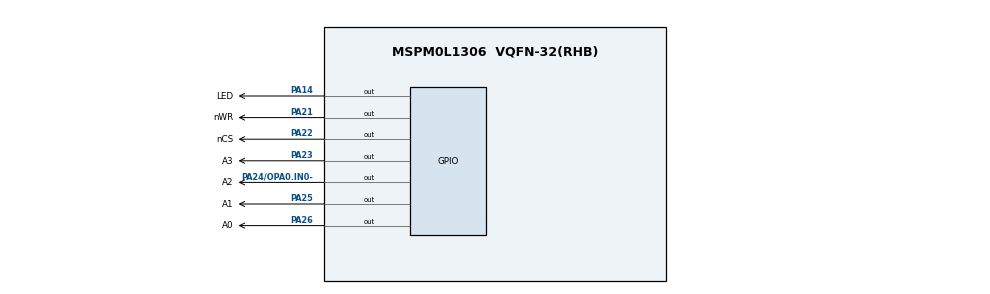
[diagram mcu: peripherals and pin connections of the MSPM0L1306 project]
/**
 * These arguments were used when this file was generated. They will be automatically applied on subsequent loads
 * via the GUI or CLI. Run CLI with '--help' for additional information on how to override these arguments.
 * @cliArgs --device "MSPM0L130X" --part "Default" --package "VQFN-32(RHB)" --product "mspm0_sdk@2.02.00.05"
 * @v2CliArgs --device "MSPM0L1306" --package "VQFN-32(RHB)" --product "mspm0_sdk@2.02.00.05"
 * @versions {"tool":"1.21.0+3721"}
 */

/**
 * Import the modules used in this configuration.
 */
const GPIO          = scripting.addModule("/ti/driverlib/GPIO", {}, false);
const GPIO1         = GPIO.addInstance();
const GPIO2         = GPIO.addInstance();
const SYSCTL        = scripting.addModule("/ti/driverlib/SYSCTL");
const ProjectConfig = scripting.addModule("/ti/project_config/ProjectConfig");

/**
 * Write custom configuration values to the imported modules.
 */
GPIO1.port                          = "PORTA";
GPIO1.portSegment                   = "Lower";
GPIO1.$name                         = "GPIO";
GPIO1.associatedPins[0].$name       = "LED";
GPIO1.associatedPins[0].pin.$assign = "PA14";

const Board = scripting.addModule("/ti/driverlib/Board", {}, false);

GPIO2.$name                         = "GPIO_MUX";
GPIO2.port                          = "PORTA";
GPIO2.portSegment                   = "Upper";
GPIO2.associatedPins.create(6);
GPIO2.associatedPins[0].$name       = "A0";
GPIO2.associatedPins[0].pin.$assign = "PA26";
GPIO2.associatedPins[1].$name       = "A1";
GPIO2.associatedPins[1].pin.$assign = "PA25";
GPIO2.associatedPins[2].$name       = "A2";
GPIO2.associatedPins[2].pin.$assign = "PA24/OPA0.IN0-";
GPIO2.associatedPins[3].$name       = "A3";
GPIO2.associatedPins[3].pin.$assign = "PA23";
GPIO2.associatedPins[4].$name       = "nCS";
GPIO2.associatedPins[4].pin.$assign = "PA22";
GPIO2.associatedPins[5].$name       = "nWR";
GPIO2.associatedPins[5].pin.$assign = "PA21";


ProjectConfig.deviceSpin = "MSPM0L1306";

/**
 * Pinmux solution for unlocked pins/peripherals. This ensures that minor changes to the automatic solver in a future
 * version of the tool will not impact the pinmux you originally saw.  These lines can be completely deleted in order to
 * re-solve from scratch.
 */
Board.peripheral.$suggestSolution          = "DEBUGSS";
Board.peripheral.swclkPin.$suggestSolution = "PA20";
Board.peripheral.swdioPin.$suggestSolution = "PA19";
SYSCTL.peripheral.$suggestSolution         = "SYSCTL";
